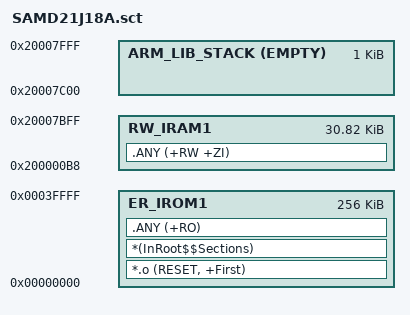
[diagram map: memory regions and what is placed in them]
#! armcc -E

;SAMD21J18A
;256KB FLASH (0x40000) @ 0x000000000
;2KB RAM (0x8000) @ 0x20000000

#if !defined(MBED_BOOT_STACK_SIZE)
  #define MBED_BOOT_STACK_SIZE 0x400
#endif

#define Stack_Size MBED_BOOT_STACK_SIZE

;SAMD21J18A: 256KB FLASH (0x40000) + 32KB RAM (0x8000)
LR_IROM1 0x00000000 0x40000  {    ; load region size_region
    ER_IROM1 0x00000000 0x40000  {  ; load address = execution address 
        *.o (RESET, +First)
        *(InRoot$$Sections)
        .ANY (+RO)
    }

    ; [RAM] Vector table dynamic copy: 45 vectors * 4 bytes = (0xB4+0x4) 8-byte alignment
    RW_IRAM1 (0x20000000+0xB8) (0x8000-0xB8-Stack_Size)  {  ; RW data
        .ANY (+RW +ZI)
    }
    ARM_LIB_STACK 0x20000000+0x8000 EMPTY -Stack_Size { ; Stack region growing down
    }
}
